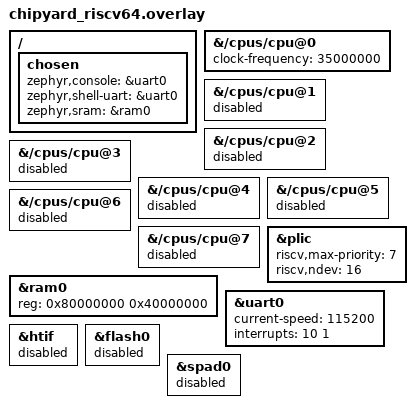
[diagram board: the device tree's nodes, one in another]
/*
 * Bench overlay for RocketArty200TDroneGemminiSaturnFp16At35Config
 * (fp16-only Saturn Rocket, 35 MHz peripheral clock).
 *   DDR   memory@80000000 (1 GiB) -> zephyr,sram = ram0
 *   uart0 serial@10020000 @115200 -> console -> /dev/ttyUSB1
 * Base dtsi defaults the console to HTIF; move it to the SiFive uart0 so
 * printk reaches ttyUSB1 (HTIF has no fesvr in the JTAG bench flow).
 */

/ {
	chosen {
		zephyr,console = &uart0;
		zephyr,shell-uart = &uart0;
		zephyr,sram = &ram0;
	};
};

&{/cpus/cpu@0} { clock-frequency = <35000000>; };
&{/cpus/cpu@1} { status = "disabled"; };
&{/cpus/cpu@2} { status = "disabled"; };
&{/cpus/cpu@3} { status = "disabled"; };
&{/cpus/cpu@4} { status = "disabled"; };
&{/cpus/cpu@5} { status = "disabled"; };
&{/cpus/cpu@6} { status = "disabled"; };
&{/cpus/cpu@7} { status = "disabled"; };

&plic { riscv,max-priority = <7>; riscv,ndev = <16>; };

&ram0 { reg = <0x80000000 0x40000000>; status = "okay"; };

&uart0 { status = "okay"; current-speed = <115200>; interrupts = <10 1>; };

&htif  { status = "disabled"; };
&flash0 { status = "disabled"; };
&spad0 { status = "disabled"; };
